# NUC200AE_v1 register map
File version: 1.0
NUC200AE_v1 SVD file
Registers are 32-bit, read-write, reset 0x0 unless marked. A register's access mark holds for its fields unless they carry their own. Offsets are from the block's base; lines under a group give offsets from that group; [hi:lo] are bit positions; {n}, {i} and the like mark numbered series; 'fields as' and 'values as' point back to an identical list; <NAME> marks a mode.

## Memory map
0x40004000 WDT size 0x8 — WDT Register Map
0x40004100 WWDT size 0x10 — WWDT Register Map
0x40008000 RTC blocks up to offset 0x90 — RTC Register Map
0x40010000 TMR01 blocks up to offset 0x3C — TIMER Register Map
0x40012000 I2C1 blocks up to offset 0x44 — I2C Register Map
0x40020000 I2C0 blocks up to offset 0x44 — I2C Register Map
0x40030000 SPI0 blocks up to offset 0x48 — SPI Register Map
0x40034000 SPI1 blocks up to offset 0x48 — SPI Register Map
0x40040000 PWMA blocks up to offset 0x98 — PWM Register Map
0x40050000 UART0 size 0x3C — UART Register Map
0x40060000 USBD blocks up to offset 0x580 — USB Register Map
0x400D0000 ACMP size 0xC — ACMP Register Map
0x400E0000 ADC blocks up to offset 0x44 — ADC Register Map
0x40100000 PS2 size 0x20 — PS2 Register Map
0x40110000 TMR23 blocks up to offset 0x3C — TIMER Register Map
0x40130000 SPI2 blocks up to offset 0x48 — SPI Register Map
0x40134000 SPI3 blocks up to offset 0x48 — SPI Register Map
0x40140000 PWMB blocks up to offset 0x98 — PWM Register Map
0x40150000 UART1 size 0x3C — UART Register Map
0x40154000 UART2 blocks up to offset 0x3C — UART Register Map
0x40180000 CAN0 blocks up to offset 0x170 — CAN Register Map
0x40184000 CAN1 blocks up to offset 0x170 — CAN Register Map
0x40190000 SC0 size 0x40 — SC Register Map
0x40194000 SC1 size 0x40 — SC Register Map
0x40198000 SC2 size 0x40 — SC Register Map
0x401A0000 I2S size 0x18 — I2S Register Map
0x50000000 GCR blocks up to offset 0x104 — GCR Register Map
0x50000200 CLK blocks up to offset 0x3C — CLK Register Map
0x50000300 INT size 0x8C — INT Register Map
0x50004000 GPIO blocks up to offset 0x350 — GPIO Register Map
{0x50008000+0x100*n} PDMA_CH{n} blocks up to offset 0x84 (n=0..8) — PDMA Register Map
0x50008E00 CRC blocks up to offset 0x8C — PDMA Register Map
0x50008F00 PDMA_GCR size 0x14 — PDMA Register Map
0x5000C000 FMC blocks up to offset 0x44 — FMC Register Map
0x50010000 EBI size 0xC — EBI Register Map
0xE000E000 SCS blocks up to offset 0xD24 — SYST_NVIC_SCS Register Map

## EBI — EBI Register Map
Base 0x50010000
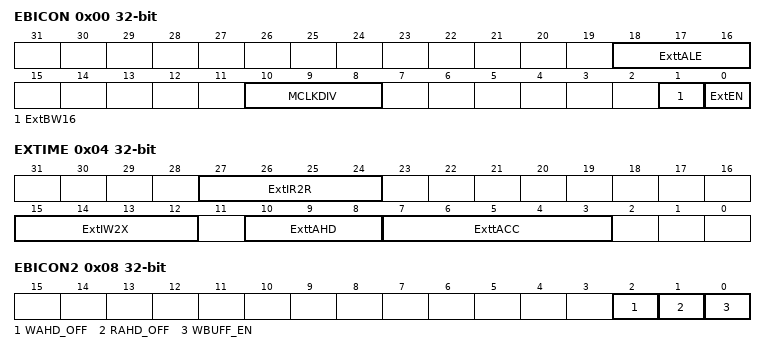
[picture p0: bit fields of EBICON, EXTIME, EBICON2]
0x00 EBICON — External Bus Interface General Control Register
  [18:16] ExttALE — Expand Time of ALE. This field is used for control the ALE pulse width (tALE) for latch the address
  [10:8] MCLKDIV — External Output Clock Divider
  [1] ExtBW16 — EBI Data Width 16-bit/8-bit. This bit defines if the data bus is 8-bit or 16-bit.
    0=EBI data width is 8-bit; 1=EBI data width is 16-bit
  [0] ExtEN — EBI Enable. This bit is the functional enable bit for EBI.
    0=EBI function Disabled; 1=EBI function Enabled
0x04 EXTIME — External Bus Interface Timing Control Register
  [27:24] ExtIR2R — Idle State Cycle Between Read-Read. When read action is finished and the next action is going to read, idle state is inserted and nCS signal return to high if ExtIR2R is not zero.
  [15:12] ExtIW2X — Idle State Cycle After Write. When write action is finished, idle state is inserted and nCS signal return to high if ExtIW2X is not zero.
  [10:8] ExttAHD — EBI Data Access Hold Time. ExttAHD defines data access hold time (tAHD).
  [7:3] ExttACC — EBI Data Access Time. ExttACC defines data access time (tACC).
0x08 EBICON2 — External Bus Interface General Control Register 2
  [2] WAHD_OFF — Access Hold Time Disable Control When Write
    0=tAHD is controlled by ExttAHD when write through EBI; 1=No tAHD when write through EBI
  [1] RAHD_OFF — Access Hold Time Disable Control When Read
    0=tAHD is controlled by ExttAHD when read through EBI; 1=No tAHD when read through EBI
  [0] WBUFF_EN — EBI Write Buffer Enable
    0=EBI write buffer disable; 1=EBI write buffer enable
